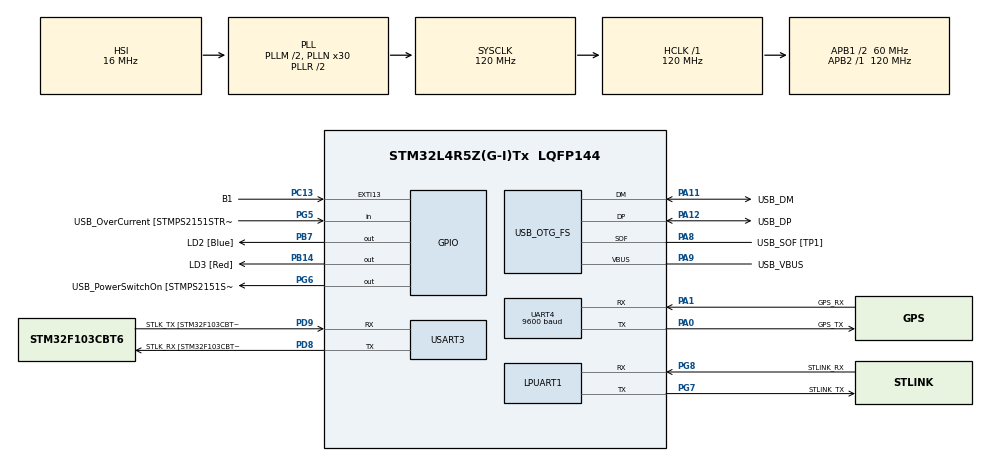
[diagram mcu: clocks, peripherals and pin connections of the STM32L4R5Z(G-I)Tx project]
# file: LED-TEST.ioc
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Mcu.Family=STM32L4
Mcu.Name=STM32L4R5Z(G-I)Tx
Mcu.Package=LQFP144
NVIC.PriorityGroup=NVIC_PRIORITYGROUP_4
PA0.GPIO_Label=GPS_TX
PA0.Mode=Asynchronous
PA0.Signal=UART4_TX
PA1.GPIO_Label=GPS_RX
PA1.Mode=Asynchronous
PA1.Signal=UART4_RX
PA10.GPIO_Label=USB_ID
PA10.Signal=USB_OTG_FS_ID
PA11.GPIO_Label=USB_DM
PA11.Mode=Device_Only
PA11.Signal=USB_OTG_FS_DM
PA12.GPIO_Label=USB_DP
PA12.Mode=Device_Only
PA12.Signal=USB_OTG_FS_DP
PA13\ (JTMS/SWDIO).GPIO_Label=TMS
PA13\ (JTMS/SWDIO).Mode=Trace_Asynchronous_SW
PA13\ (JTMS/SWDIO).Signal=SYS_JTMS-SWDIO
PA14\ (JTCK/SWCLK).GPIO_Label=TCK
PA14\ (JTCK/SWCLK).Mode=Trace_Asynchronous_SW
PA14\ (JTCK/SWCLK).Signal=SYS_JTCK-SWCLK
PA8.GPIO_Label=USB_SOF [TP1]
PA8.Mode=Activate_SOF_FS
PA8.Signal=USB_OTG_FS_SOF
PA9.GPIO_Label=USB_VBUS
PA9.Mode=Activate_VBUS
PA9.Signal=USB_OTG_FS_VBUS
PB14.GPIO_Label=LD3 [Red]
PB14.Signal=GPIO_Output
PB3\ (JTDO/TRACESWO).GPIO_Label=SWO
PB3\ (JTDO/TRACESWO).Mode=Trace_Asynchronous_SW
PB3\ (JTDO/TRACESWO).Signal=SYS_JTDO-SWO
PB7.GPIO_Label=LD2 [Blue]
PB7.Signal=GPIO_Output
PC13.GPIO_Label=B1
PC13.Signal=GPXTI13
PC14-OSC32_IN\ (PC14).Mode=LSE-External-Oscillator
PC14-OSC32_IN\ (PC14).Signal=RCC_OSC32_IN
PC15-OSC32_OUT\ (PC15).Mode=LSE-External-Oscillator
PC15-OSC32_OUT\ (PC15).Signal=RCC_OSC32_OUT
PD8.GPIO_Label=STLK_RX [STM32F103CBT6_PA3]
PD8.Mode=Asynchronous
PD8.Signal=USART3_TX
PD9.GPIO_Label=STLK_TX [STM32F103CBT6_PA2]
PD9.Mode=Asynchronous
PD9.Signal=USART3_RX
PG5.GPIO_Label=USB_OverCurrent [STMPS2151STR_FAULT]
PG5.Signal=GPIO_Input
PG6.GPIO_Label=USB_PowerSwitchOn [STMPS2151STR_EN]
PG6.Signal=GPIO_Output
PG7.GPIO_Label=STLINK_TX
PG7.Mode=Asynchronous
PG7.Signal=LPUART1_TX
PG8.GPIO_Label=STLINK_RX
PG8.Mode=Asynchronous
PG8.Signal=LPUART1_RX
PH0-OSC_IN\ (PH0).Signal=RCC_OSC_IN
PH1-OSC_OUT\ (PH1).Signal=RCC_OSC_OUT
ProjectManager.HeapSize=0x200
ProjectManager.StackSize=0x400
ProjectManager.TargetToolchain=Makefile
RCC.48MHZClocksFreq_Value=24000000
RCC.ADCFreq_Value=96000000
RCC.AHBFreq_Value=120000000
RCC.APB1CLKDivider=RCC_HCLK_DIV2
RCC.APB1Freq_Value=60000000
RCC.APB1TimFreq_Value=120000000
RCC.APB2Freq_Value=120000000
RCC.APB2TimFreq_Value=120000000
RCC.CK48CLockSelection=RCC_USBCLKSOURCE_HSI48
RCC.CortexFreq_Value=120000000
RCC.HCLKFreq_Value=120000000
RCC.HSE_VALUE=8000000
RCC.HSI48_VALUE=48000000
RCC.HSI_VALUE=16000000
RCC.MSI_VALUE=4000000
RCC.PLLM1=2
RCC.PLLMUL=RCC_PLL_MUL9
RCC.PLLN=30
RCC.PLLSAI1N=12
RCC.PLLSourceVirtual=RCC_PLLSOURCE_HSI
RCC.PRESCALERUSB=RCC_USBCLKSOURCE_PLL_DIV1_5
RCC.SYSCLKFreq_VALUE=120000000
RCC.SYSCLKSource=RCC_SYSCLKSOURCE_PLLCLK
RCC.SYSCLKSourceVirtual=RCC_SYSCLKSOURCE_PLLCLK
RCC.USBFreq_Value=48000000
RCC.VCOOutputFreq_Value=240000000
UART4.BaudRate=9600
USART3.VirtualMode-Asynchronous=VM_ASYNC
USB_OTG_FS.VirtualMode=Device_Only
board=NUCLEO-L4R5ZI

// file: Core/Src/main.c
/* USER CODE BEGIN Header */
/**
  ******************************************************************************
  * @file           : main.c
  * @brief          : Main program body
  ******************************************************************************
  * @attention
  *
  * Copyright (c) 2023 STMicroelectronics.
  * All rights reserved.
  *
  * This software is licensed under terms that can be found in the LICENSE file
  * in the root directory of this software component.
  * If no LICENSE file comes with this software, it is provided AS-IS.
  *
  ******************************************************************************
  */
/* USER CODE END Header */
#include "main.h"
#include "usart.h"
#include "usb_otg.h"
#include "gpio.h"

#include <stdio.h>

void SystemClock_Config(void);
/* USER CODE BEGIN PFP */

#ifdef __GNUC__
#define PUTCHAR_PROTOTYPE int __io_putchar(int ch)
#else
#define PUTCHAR_PROTOTYPE int fputc(int ch, FILE *f)
#endif

PUTCHAR_PROTOTYPE
{
	HAL_UART_Transmit(&huart3, (uint8_t *)&ch, 1, HAL_MAX_DELAY);
	return ch;
}

/* USER CODE END PFP */

int main(void)
{

  /* MCU Configuration--------------------------------------------------------*/

  /* Reset of all peripherals, Initializes the Flash interface and the Systick. */
  HAL_Init();

  /* Configure the system clock */
  SystemClock_Config();

  /* Initialize all configured peripherals */
  MX_GPIO_Init();
  MX_LPUART1_UART_Init();
  MX_UART4_Init();
  MX_USART3_UART_Init();
  MX_USB_OTG_FS_PCD_Init();

  /* Infinite loop */
  while (1)
  {

    /* USER CODE BEGIN 3 */
	//HAL_GPIO_TogglePin(GPIOB, GPIO_PIN_14);
	//HAL_Delay(100);
	printf("Test\n");
	HAL_Delay(1000);
  }
  /* USER CODE END 3 */
}

void SystemClock_Config(void)
{
  RCC_OscInitTypeDef RCC_OscInitStruct = {0};
  RCC_ClkInitTypeDef RCC_ClkInitStruct = {0};

  /** Configure the main internal regulator output voltage
  */
  if (HAL_PWREx_ControlVoltageScaling(PWR_REGULATOR_VOLTAGE_SCALE1_BOOST) != HAL_OK)
  {
    Error_Handler();
  }

  /** Initializes the RCC Oscillators according to the specified parameters
  * in the RCC_OscInitTypeDef structure.
  */
  RCC_OscInitStruct.OscillatorType = RCC_OSCILLATORTYPE_HSI48|RCC_OSCILLATORTYPE_HSI;
  RCC_OscInitStruct.HSIState = RCC_HSI_ON;
  RCC_OscInitStruct.HSI48State = RCC_HSI48_ON;
  RCC_OscInitStruct.HSICalibrationValue = RCC_HSICALIBRATION_DEFAULT;
  RCC_OscInitStruct.PLL.PLLState = RCC_PLL_ON;
  RCC_OscInitStruct.PLL.PLLSource = RCC_PLLSOURCE_HSI;
  RCC_OscInitStruct.PLL.PLLM = 2;
  RCC_OscInitStruct.PLL.PLLN = 30;
  RCC_OscInitStruct.PLL.PLLP = RCC_PLLP_DIV2;
  RCC_OscInitStruct.PLL.PLLQ = RCC_PLLQ_DIV2;
  RCC_OscInitStruct.PLL.PLLR = RCC_PLLR_DIV2;
  if (HAL_RCC_OscConfig(&RCC_OscInitStruct) != HAL_OK)
  {
    Error_Handler();
  }

  /** Initializes the CPU, AHB and APB buses clocks
  */
  RCC_ClkInitStruct.ClockType = RCC_CLOCKTYPE_HCLK|RCC_CLOCKTYPE_SYSCLK
                              |RCC_CLOCKTYPE_PCLK1|RCC_CLOCKTYPE_PCLK2;
  RCC_ClkInitStruct.SYSCLKSource = RCC_SYSCLKSOURCE_PLLCLK;
  RCC_ClkInitStruct.AHBCLKDivider = RCC_SYSCLK_DIV1;
  RCC_ClkInitStruct.APB1CLKDivider = RCC_HCLK_DIV2;
  RCC_ClkInitStruct.APB2CLKDivider = RCC_HCLK_DIV1;

  if (HAL_RCC_ClockConfig(&RCC_ClkInitStruct, FLASH_LATENCY_5) != HAL_OK)
  {
    Error_Handler();
  }
}

void Error_Handler(void)
{
  __disable_irq();
  while (1)
  {
  }
}
